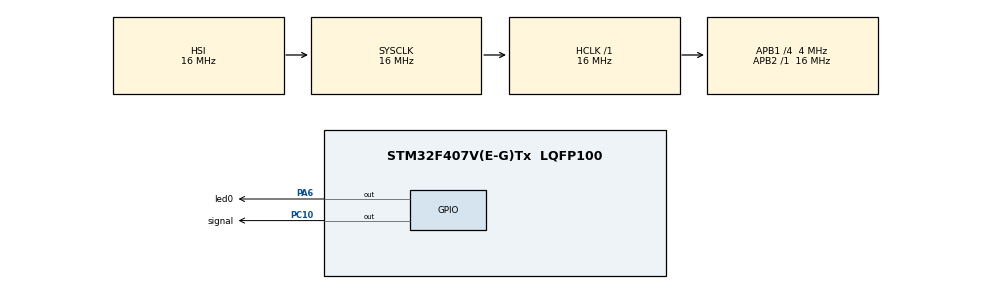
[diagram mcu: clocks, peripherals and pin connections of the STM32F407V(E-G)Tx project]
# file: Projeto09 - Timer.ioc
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Mcu.Family=STM32F4
Mcu.Name=STM32F407V(E-G)Tx
Mcu.Package=LQFP100
NVIC.PriorityGroup=NVIC_PRIORITYGROUP_4
PA6.GPIO_Label=led0
PA6.Signal=GPIO_Output
PC10.GPIO_Label=signal
PC10.Signal=GPIO_Output
ProjectManager.HeapSize=0x200
ProjectManager.StackSize=0x400
ProjectManager.TargetToolchain=STM32CubeIDE
RCC.AHBFreq_Value=16000000
RCC.APB1CLKDivider=RCC_HCLK_DIV4
RCC.APB1Freq_Value=4000000
RCC.APB1TimFreq_Value=8000000
RCC.APB2Freq_Value=16000000
RCC.CortexFreq_Value=16000000
RCC.HSE_VALUE=25000000
RCC.HSI_VALUE=16000000
RCC.LSE_VALUE=32768
RCC.SYSCLKFreq_VALUE=16000000
RCC.VCOOutputFreq_Value=192000000
TIM2.Prescaler=8-1
VP_TIM2_VS_ClockSourceINT.Mode=Internal
board=custom

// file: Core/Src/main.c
/* USER CODE BEGIN Header */
/**
  ******************************************************************************
  * @file           : main.c
  * @brief          : Main program body
  ******************************************************************************
  * @attention
  *
  * Copyright (c) 2022 STMicroelectronics.
  * All rights reserved.
  *
  * This software is licensed under terms that can be found in the LICENSE file
  * in the root directory of this software component.
  * If no LICENSE file comes with this software, it is provided AS-IS.
  *
  ******************************************************************************
  */
/* USER CODE END Header */
#include "main.h"

 TIM_HandleTypeDef htim2;

void SystemClock_Config(void);
static void MX_GPIO_Init(void);
static void MX_TIM2_Init(void);
/* USER CODE BEGIN PFP */

void delay_us(uint32_t us);

/* USER CODE END PFP */

int main(void)
{

  /* MCU Configuration--------------------------------------------------------*/

  /* Reset of all peripherals, Initializes the Flash interface and the Systick. */
  HAL_Init();

  /* Configure the system clock */
  SystemClock_Config();

  /* Initialize all configured peripherals */
  MX_GPIO_Init();
  MX_TIM2_Init();
  /* USER CODE BEGIN 2 */

  HAL_TIM_Base_Start(&htim2);

  /* USER CODE END 2 */

  /* Infinite loop */
  /* USER CODE BEGIN WHILE */
  while (1)
  {
	  HAL_GPIO_TogglePin(led0_GPIO_Port, led0_Pin);
	  HAL_GPIO_TogglePin(signal_GPIO_Port, signal_Pin);
	  delay_us(1000000);
    /* USER CODE END WHILE */

  }
}

void SystemClock_Config(void)
{
  RCC_OscInitTypeDef RCC_OscInitStruct = {0};
  RCC_ClkInitTypeDef RCC_ClkInitStruct = {0};

  /** Configure the main internal regulator output voltage
  */
  __HAL_RCC_PWR_CLK_ENABLE();
  __HAL_PWR_VOLTAGESCALING_CONFIG(PWR_REGULATOR_VOLTAGE_SCALE1);

  /** Initializes the RCC Oscillators according to the specified parameters
  * in the RCC_OscInitTypeDef structure.
  */
  RCC_OscInitStruct.OscillatorType = RCC_OSCILLATORTYPE_HSI;
  RCC_OscInitStruct.HSIState = RCC_HSI_ON;
  RCC_OscInitStruct.HSICalibrationValue = RCC_HSICALIBRATION_DEFAULT;
  RCC_OscInitStruct.PLL.PLLState = RCC_PLL_NONE;
  if (HAL_RCC_OscConfig(&RCC_OscInitStruct) != HAL_OK)
  {
    Error_Handler();
  }

  /** Initializes the CPU, AHB and APB buses clocks
  */
  RCC_ClkInitStruct.ClockType = RCC_CLOCKTYPE_HCLK|RCC_CLOCKTYPE_SYSCLK
                              |RCC_CLOCKTYPE_PCLK1|RCC_CLOCKTYPE_PCLK2;
  RCC_ClkInitStruct.SYSCLKSource = RCC_SYSCLKSOURCE_HSI;
  RCC_ClkInitStruct.AHBCLKDivider = RCC_SYSCLK_DIV1;
  RCC_ClkInitStruct.APB1CLKDivider = RCC_HCLK_DIV4;
  RCC_ClkInitStruct.APB2CLKDivider = RCC_HCLK_DIV1;

  if (HAL_RCC_ClockConfig(&RCC_ClkInitStruct, FLASH_LATENCY_0) != HAL_OK)
  {
    Error_Handler();
  }
}

static void MX_TIM2_Init(void)
{

  TIM_ClockConfigTypeDef sClockSourceConfig = {0};
  TIM_MasterConfigTypeDef sMasterConfig = {0};

  htim2.Instance = TIM2;
  htim2.Init.Prescaler = 8-1;
  htim2.Init.CounterMode = TIM_COUNTERMODE_UP;
  htim2.Init.Period = 4294967295;
  htim2.Init.ClockDivision = TIM_CLOCKDIVISION_DIV1;
  htim2.Init.AutoReloadPreload = TIM_AUTORELOAD_PRELOAD_DISABLE;
  if (HAL_TIM_Base_Init(&htim2) != HAL_OK)
  {
    Error_Handler();
  }
  sClockSourceConfig.ClockSource = TIM_CLOCKSOURCE_INTERNAL;
  if (HAL_TIM_ConfigClockSource(&htim2, &sClockSourceConfig) != HAL_OK)
  {
    Error_Handler();
  }
  sMasterConfig.MasterOutputTrigger = TIM_TRGO_RESET;
  sMasterConfig.MasterSlaveMode = TIM_MASTERSLAVEMODE_DISABLE;
  if (HAL_TIMEx_MasterConfigSynchronization(&htim2, &sMasterConfig) != HAL_OK)
  {
    Error_Handler();
  }

}

static void MX_GPIO_Init(void)
{
  GPIO_InitTypeDef GPIO_InitStruct = {0};

  /* GPIO Ports Clock Enable */
  __HAL_RCC_GPIOA_CLK_ENABLE();
  __HAL_RCC_GPIOC_CLK_ENABLE();

  /*Configure GPIO pin Output Level */
  HAL_GPIO_WritePin(led0_GPIO_Port, led0_Pin, GPIO_PIN_RESET);

  /*Configure GPIO pin Output Level */
  HAL_GPIO_WritePin(signal_GPIO_Port, signal_Pin, GPIO_PIN_RESET);

  /*Configure GPIO pin : led0_Pin */
  GPIO_InitStruct.Pin = led0_Pin;
  GPIO_InitStruct.Mode = GPIO_MODE_OUTPUT_PP;
  GPIO_InitStruct.Pull = GPIO_NOPULL;
  GPIO_InitStruct.Speed = GPIO_SPEED_FREQ_LOW;
  HAL_GPIO_Init(led0_GPIO_Port, &GPIO_InitStruct);

  /*Configure GPIO pin : signal_Pin */
  GPIO_InitStruct.Pin = signal_Pin;
  GPIO_InitStruct.Mode = GPIO_MODE_OUTPUT_PP;
  GPIO_InitStruct.Pull = GPIO_NOPULL;
  GPIO_InitStruct.Speed = GPIO_SPEED_FREQ_LOW;
  HAL_GPIO_Init(signal_GPIO_Port, &GPIO_InitStruct);

}

/* USER CODE BEGIN 4 */

/**
 *  Ele já estoura em 1us
 */
void delay_us(uint32_t us)
{
	__HAL_TIM_SET_COUNTER(&htim2, 0);			/**< Setando o contador em zero */
	while(__HAL_TIM_GET_COUNTER(&htim2) < us);	/**< Fica preso até o valor de us seja verdadeiro */
}

/* USER CODE END 4 */

void Error_Handler(void)
{
  __disable_irq();
  while (1)
  {
  }
}
